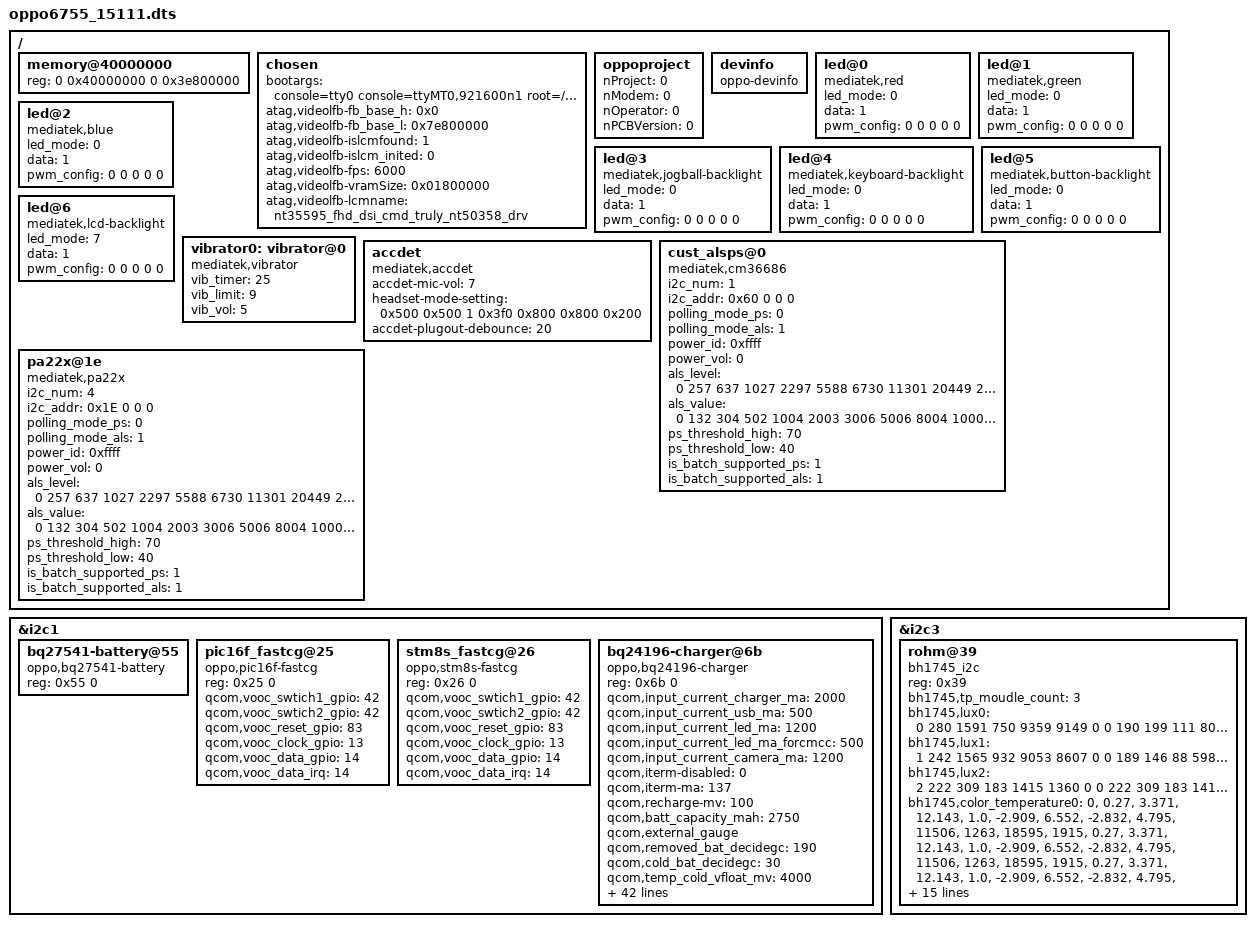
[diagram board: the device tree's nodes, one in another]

/dts-v1/;

#include "mt6755.dtsi"

//Fuchun.Liao@Mobile.BSP.CHG 2016-02-24 modify 
#include "mt6351.dtsi"
//Fuchun.Liao modify end

/ {
	memory@40000000 {
		device_type = "memory";
		reg = <0 0x40000000 0 0x3e800000>;
	};
	/* chosen */
	chosen {
		bootargs = "console=tty0 console=ttyMT0,921600n1 root=/dev/ram initrd=0x44000000,0x4b434e loglevel=8";

		/* fpga may has no lk, we need to specify display info here */
		/* fb buffer is reserved using this dts by memory node above */
		atag,videolfb-fb_base_h = <0x0>;
		atag,videolfb-fb_base_l = <0x7e800000>;
		atag,videolfb-islcmfound = <1>;
		/* because no lk, so lcm is not inited */
		atag,videolfb-islcm_inited = <0>;
		atag,videolfb-fps= <6000>;
		atag,videolfb-vramSize= <0x01800000>;
		atag,videolfb-lcmname= "nt35595_fhd_dsi_cmd_truly_nt50358_drv";
	};
	//#ifdef VENDOR_EDIT yixue.ge@bsp.drv add for oppo prject
	/*oppoproject?*/
	oppoproject {
		nProject = <0>;
		nModem = <0>;
		nOperator = <0>;
		nPCBVersion = <0>;
	};
	//#endif

	//#ifdef VENDOR_EDIT Yixue.ge@BSP.drv, 2016/01/21, Add for support oppo dev info
	devinfo {
        compatible = "oppo-devinfo";
        //Hw,sub_hwid_1 = <&msm_gpio 86 0x00>;
        //Hw,sub_hwid_2= <&msm_gpio 111 0x00>;
        //pinctrl-names = "default";
        //pinctrl-0 = <&hw_sub_gpio1_active &hw_sub_gpio2_active>;
	};
	//#endif

	led@0 {
		compatible = "mediatek,red";
		led_mode = <0>;
		data = <1>;
		pwm_config = <0 0 0 0 0>;
	};
	led@1 {
		compatible = "mediatek,green";
		led_mode = <0>;
		data = <1>;
		pwm_config = <0 0 0 0 0>;
	};
	led@2 {
		compatible = "mediatek,blue";
		led_mode = <0>;
		data = <1>;
		pwm_config = <0 0 0 0 0>;
	};
	led@3 {
		compatible = "mediatek,jogball-backlight";
		led_mode = <0>;
		data = <1>;
		pwm_config = <0 0 0 0 0>;
	};
	led@4 {
		compatible = "mediatek,keyboard-backlight";
		led_mode = <0>;
		data = <1>;
		pwm_config = <0 0 0 0 0>;
	};
	led@5 {
		compatible = "mediatek,button-backlight";
		led_mode = <0>;
		data = <1>;
		pwm_config = <0 0 0 0 0>;
	};
	led@6 {
		compatible = "mediatek,lcd-backlight";
		led_mode = <7>;
		data = <1>;
		pwm_config = <0 0 0 0 0>;
	};
	vibrator0:vibrator@0 {
		compatible = "mediatek,vibrator";
		vib_timer = <25>;
		vib_limit = <9>;
		vib_vol= <5>;
	};
	accdet {
		compatible = "mediatek,accdet";
		accdet-mic-vol = <7>;
		headset-mode-setting = <0x500 0x500 1 0x3f0 0x800 0x800 0x200>;
		accdet-plugout-debounce = <20>;
	};
/*  start sensor */
	cust_alsps@0 {
		compatible 				= "mediatek,cm36686";
		i2c_num 				= <1>;
		i2c_addr 				= <0x60 0 0 0>;
		polling_mode_ps			= <0>;
		polling_mode_als		= <1>;
		power_id   				= <0xffff>;
		power_vol  				= <0>;
		/* Total has 15 level*/
		als_level  				= <0 257 637 1027 2297 5588 6730 11301 20449 25768 31122 45552 57937 57937 57937>;
		/*  Total has 16 range*/
		als_value  				= <0 132 304 502 1004 2003 3006 5006 8004 10000 12000 16000 20000 20000 20000 20000>;
		ps_threshold_high		=  <70>;
		ps_threshold_low		=  <40>;
		is_batch_supported_ps	= <1>;
		is_batch_supported_als	= <1>;
	};
	pa22x@1e {
		compatible 				= "mediatek,pa22x";
		i2c_num 				= <4>;
		i2c_addr 				= <0x1E 0 0 0>;
		polling_mode_ps			= <0>;
		polling_mode_als		= <1>;
		power_id   				= <0xffff>;
		power_vol  				= <0>;
		/* Total has 15 level*/
		als_level  				= <0 257 637 1027 2297 5588 6730 11301 20449 25768 31122 45552 57937 57937 57937>;
		/*  Total has 16 range*/
		als_value  				= <0 132 304 502 1004 2003 3006 5006 8004 10000 12000 16000 20000 20000 20000 20000>;
		ps_threshold_high		=  <70>;
		ps_threshold_low		=  <40>;
		is_batch_supported_ps	= <1>;
		is_batch_supported_als	= <1>;
	};
/* end sensor */
};

//soc {
		&i2c1 {
//#ifdef VENDOR_EDIT//Fanhong.Kong@ProDrv.CHG,modified 2015.9.30 for charging			
			bq27541-battery@55 {
				status = "okay";
				compatible = "oppo,bq27541-battery";
				reg = <0x55 0>;
			};
			pic16f_fastcg@25{
			status = "okay";
			compatible = "oppo,pic16f-fastcg";
			reg = <0x25 0>;
			

			qcom,vooc_swtich1_gpio		= <42>;
			qcom,vooc_swtich2_gpio 		= <42>;
			
			qcom,vooc_reset_gpio 		= <83>;
			qcom,vooc_clock_gpio 		= <13>;
			qcom,vooc_data_gpio 		= <14>;
			qcom,vooc_data_irq 		= <14>;
			};
			
			stm8s_fastcg@26{
			status = "okay";
			compatible = "oppo,stm8s-fastcg";
			reg = <0x26 0>;
			
			qcom,vooc_swtich1_gpio		= <42>;
			qcom,vooc_swtich2_gpio 		= <42>;
			
			qcom,vooc_reset_gpio 		= <83>;
			qcom,vooc_clock_gpio 		= <13>;
			qcom,vooc_data_gpio 		= <14>;
			qcom,vooc_data_irq 		= <14>;
			};
			
			bq24196-charger@6b {
			status = "okay";
			compatible = "oppo,bq24196-charger";
			reg = <0x6b 0>;
						
			qcom,input_current_charger_ma = <2000>;
			qcom,input_current_usb_ma = <500>;
			qcom,input_current_led_ma = <1200>;
			qcom,input_current_led_ma_forcmcc = <500>;
			qcom,input_current_camera_ma = <1200>;
			qcom,iterm-disabled = <0>;
			qcom,iterm-ma = <137>;			
			qcom,recharge-mv = <100>;
			qcom,batt_capacity_mah = <2750>;
			//qcom,suspend_after_full;
			qcom,external_gauge;
			
			qcom,removed_bat_decidegc = <190>;  /*<-19C*/
			
			qcom,cold_bat_decidegc = <30>;  /*-3C~0C*/
			qcom,temp_cold_vfloat_mv = <4000>;
			qcom,temp_cold_fastchg_current_ma = <285>;

			qcom,little_cold_bat_decidegc = <0>;	/*0C~5C*/
			qcom,temp_little_cold_vfloat_mv = <4320>;
			qcom,temp_little_cold_fastchg_current_ma = <372>;
			
			qcom,cool_bat_decidegc = <50>;	/*5C~12C*/
			qcom,temp_cool_vfloat_mv = <4320>;
			qcom,temp_cool_fastchg_current_ma_high = <620>;
			qcom,temp_cool_fastchg_current_ma_low = <372>;
			
			qcom,little_cool_bat_decidegc = <120>;	/*12C~16C*/
			qcom,temp_little_cool_vfloat_mv = <4320>;
			qcom,temp_little_cool_fastchg_current_ma = <1100>;	
			
			qcom,normal_bat_decidegc = <160>;	/*16C~45C*/
			qcom,temp_normal_fastchg_current_ma = <2000>;
			qcom,temp_normal_vfloat_mv_normalchg = <4320>;
			qcom,temp_normal_vfloat_mv_voocchg = <4352>;
			
			qcom,warm_bat_decidegc = <450>;		/*45C~53C*/
			qcom,temp_warm_vfloat_mv = <4100>;
			qcom,temp_warm_fastchg_current_ma = <688>;
			
			qcom,hot_bat_decidegc = <530>;
			
			qcom,non_standard_vfloat_mv = <4000>;
			qcom,non_standard_fastchg_current_ma = <512>;

			qcom,non_standard_vfloat_sw_limit = <3950>;
			qcom,cold_vfloat_sw_limit = <3950>;
			qcom,little_cold_vfloat_sw_limit = <4270>;
			qcom,cool_vfloat_sw_limit = <4270>;
			qcom,little_cool_vfloat_sw_limit = <4270>;
			qcom,normal_vfloat_sw_limit = <4270>;
			qcom,warm_vfloat_sw_limit = <4050>;
			
			qcom,short_c_bat_cv_mv = <4270>;
			qcom,short_c_bat_vfloat_mv = <3650>;
			qcom,short_c_bat_fastchg_current_ma = <512>;
			
			qcom,short_c_bat_vfloat_sw_limit = <3600>;
			
			qcom,max_chg_time_sec = <36000>;
			qcom,charger_hv_thr = <5800>;
			qcom,charger_lv_thr = <3400>;
			qcom,vbatt_full_thr = <4400>;
			qcom,vbatt_hv_thr = <4500>;
			qcom,vfloat_step_mv = <16>;
			qcom,vooc_project;
			qcom,chg_ctrl_by_lcd;
			qcom,chg_ctrl_by_camera;
			qcom,check_batt_full_by_sw;
			
			};
//#endif/*VENDOR_EDIT*/	


		};
	//#ifdef VENDOR_EDIT//zhihong.lu@BSP.sensor,2016/6/12,add als_only device
	&i2c3 {
		rohm@39 {
				status = "okay";
                compatible = "bh1745_i2c";
                reg = <0x39>;
                bh1745,tp_moudle_count = <3>;
                bh1745,lux0 = <
                    0           /* module id */
                    280         /* [golden judge] */
                    1591 750    /* red */
                    9359 9149   /* green */
                    0 0         /* blue */
                    190         /* [white judge] */
                    199 111     /* red */
                    806 741     /* green */
                    0 0         /* blue */
                    685         /* [black judge] */
                    3735 719    /* red */
                    23880 21540 /* green */
                    0 0         /* blue */
                >;
                bh1745,lux1 = <
                    1           /* module id */
                    242         /* [golden judge] */
                    1565 932    /* red */
                    9053 8607   /* green */
                    0 0         /* blue */
                    189         /* [white judge] */
                    146 88      /* red */
                    598 533     /* green */
                    0 0         /* blue */
                    1040        /* [black judge] */
                    1911 310    /* red */
                    11509 9976  /* green */
                    0 0         /* blue */
                >;
                bh1745,lux2 = <
                    2           /* module id */
                    222         /* [golden judge] */
                    309 183     /* red */
                    1415 1360   /* green */
                    0 0         /* blue */
                    222         /* [white judge] */
                    309 183     /* red */
                    1415 1360     /* green */
                    0 0         /* blue */
                    222         /* [black judge] */
                    309 183    /* red */
                    1415 1360 /* green */
                    0 0         /* blue */
                >;

                bh1745,color_temperature0 =
                    "0",                                 /* module id */
                    "0.27",                              /* [golden judge] */
                    "3.371","12.143","1.0",              /* beff */
                    "-2.909","6.552","-2.832","4.795",   /* color */
                    "11506","1263","18595","1915",       /* cct_eff */
                    "0.27",                              /* [white judge] */
                    "3.371","12.143","1.0",              /* beff */
                    "-2.909","6.552","-2.832","4.795",   /* color */
                    "11506","1263","18595","1915",       /* cct_eff */
                    "0.27",                              /* [black judge] */
                    "3.371","12.143","1.0",              /* beff */
                    "-2.909","6.552","-2.832","4.795",   /* color */
                    "11506","1263","18595","1915"        /* cct_eff */
                ;
                bh1745,color_temperature1 =
                    "1",                                 /* module id */
                    "0.27",                              /* [golden judge] */
                    "3.371","12.143","1.0",              /* beff */
                    "-2.909","6.552","-2.832","4.795",   /* color */
                    "11506","1263","18595","1915",       /* cct_eff */
                    "0.27",                              /* [white judge] */
                    "3.371","12.143","1.0",              /* beff */
                    "-2.909","6.552","-2.832","4.795",   /* color */
                    "11506","1263","18595","1915",       /* cct_eff */
                    "0.27",                              /* [black judge] */
                    "3.371","12.143","1.0",              /* beff */
                    "-2.909","6.552","-2.832","4.795",   /* color */
                    "11506","1263","18595","1915"        /* cct_eff */
                ;
                bh1745,color_temperature2 =
                    "2",                                 /* module id */
                    "0.27",                              /* [golden judge] */
                    "3.371","12.143","1.0",              /* beff */
                    "-2.909","6.552","-2.832","4.795",   /* color */
                    "11506","1263","18595","1915",       /* cct_eff */
                    "0.27",                              /* [white judge] */
                    "3.371","12.143","1.0",              /* beff */
                    "-2.909","6.552","-2.832","4.795",   /* color */
                    "11506","1263","18595","1915",       /* cct_eff */
                    "0.27",                              /* [black judge] */
                    "3.371","12.143","1.0",              /* beff */
                    "-2.909","6.552","-2.832","4.795",   /* color */
                    "11506","1263","18595","1915"        /* cct_eff */
                ;
            };
            /* Added end by wenshengfan,2015/12/7 */
		}; //&i2c3
	//#endif/*VENDOR_EDIT*/	
//	}; /* soc */
